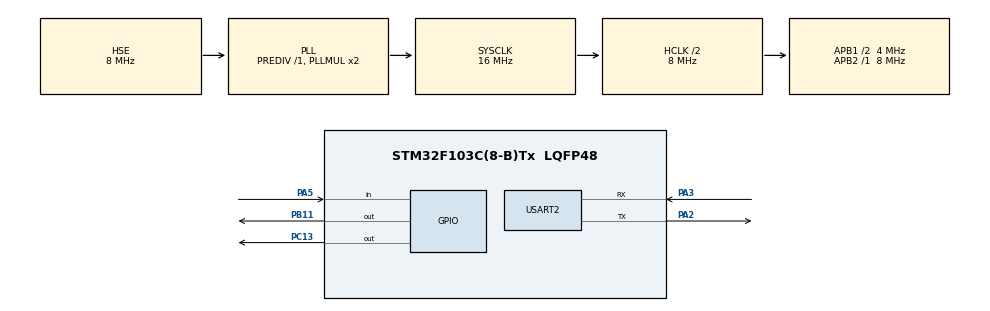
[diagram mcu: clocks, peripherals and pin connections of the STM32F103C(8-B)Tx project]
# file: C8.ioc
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Mcu.Family=STM32F1
RCC.PLLSourceVirtual=RCC_PLLSOURCE_HSE
PC15-OSC32_OUT.Mode=LSE-External-Oscillator
PD1-OSC_OUT.Mode=HSE-External-Oscillator
PC13-TAMPER-RTC.Signal=GPIO_Output
PD0-OSC_IN.Signal=RCC_OSC_IN
RCC.APB1CLKDivider=RCC_HCLK_DIV2
PC14-OSC32_IN.Signal=RCC_OSC32_IN
PB11.Signal=GPIO_Output
RCC.SYSCLKSource=RCC_SYSCLKSOURCE_PLLCLK
ProjectManager.StackSize=0x400
PD1-OSC_OUT.Signal=RCC_OSC_OUT
PA13.Signal=SYS_JTMS-SWDIO
PA3.Mode=Asynchronous
ProjectManager.TargetToolchain=STM32CubeIDE
RCC.HCLKFreq_Value=8000000
RCC.APB2TimFreq_Value=8000000
RCC.USBFreq_Value=16000000
PC15-OSC32_OUT.Signal=RCC_OSC32_OUT
RCC.AHBFreq_Value=8000000
PD0-OSC_IN.Mode=HSE-External-Oscillator
PA5.Signal=GPIO_Input
board=custom
RCC.APB2Freq_Value=8000000
PC14-OSC32_IN.Mode=LSE-External-Oscillator
PA14.Mode=Serial_Wire
RCC.AHBCLKDivider=RCC_SYSCLK_DIV2
PA13.Mode=Serial_Wire
Mcu.Name=STM32F103C(8-B)Tx
PA2.Signal=USART2_TX
RCC.SYSCLKFreq_VALUE=16000000
Mcu.Package=LQFP48
USART2.VirtualMode=VM_ASYNC
PA14.Signal=SYS_JTCK-SWCLK
ProjectManager.HeapSize=0x200
NVIC.PriorityGroup=NVIC_PRIORITYGROUP_4
RCC.APB1TimFreq_Value=8000000
PA2.Mode=Asynchronous
RCC.APB1Freq_Value=4000000
PA3.Signal=USART2_RX

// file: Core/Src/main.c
/* USER CODE BEGIN Header */
/**
  ******************************************************************************
  * @file           : main.c
  * @brief          : Main program body
  ******************************************************************************
  * @attention
  *
  * <h2><center>&copy; Copyright (c) 2025 STMicroelectronics.
  * All rights reserved.</center></h2>
  *
  * This software component is licensed by ST under BSD 3-Clause license,
  * the "License"; You may not use this file except in compliance with the
  * License. You may obtain a copy of the License at:
  *                        opensource.org/licenses/BSD-3-Clause
  *
  ******************************************************************************
  */
/* USER CODE END Header */
#include "main.h"

UART_HandleTypeDef huart2;

void SystemClock_Config(void);
static void MX_GPIO_Init(void);
static void MX_USART2_UART_Init(void);

int main(void)
{

  /* MCU Configuration--------------------------------------------------------*/

  /* Reset of all peripherals, Initializes the Flash interface and the Systick. */
  HAL_Init();

  /* Configure the system clock */
  SystemClock_Config();

  /* Initialize all configured peripherals */
  MX_GPIO_Init();
  MX_USART2_UART_Init();

  /* Infinite loop */
  /* USER CODE BEGIN WHILE */
  char buf[100];
  while (1)
  {
    /* USER CODE END WHILE */

    /* USER CODE BEGIN 3 */
	  strcpy(buf, "Hello K66 UET");
	  HAL_UART_Transmit(&huart2,(uint8_t*)buf, strlen(buf), HAL_MAX_DELAY);
	  HAL_GPIO_TogglePin(GPIOB, GPIO_PIN_11);
	  GPIO_PinState pin_state =  HAL_GPIO_ReadPin(GPIOA, GPIO_PIN_5);
	  HAL_GPIO_WritePin(GPIOC, GPIO_PIN_13, pin_state);

	  HAL_Delay(200);
  }
  /* USER CODE END 3 */
}

void SystemClock_Config(void)
{
  RCC_OscInitTypeDef RCC_OscInitStruct = {0};
  RCC_ClkInitTypeDef RCC_ClkInitStruct = {0};

  /** Initializes the RCC Oscillators according to the specified parameters
  * in the RCC_OscInitTypeDef structure.
  */
  RCC_OscInitStruct.OscillatorType = RCC_OSCILLATORTYPE_HSE;
  RCC_OscInitStruct.HSEState = RCC_HSE_ON;
  RCC_OscInitStruct.HSEPredivValue = RCC_HSE_PREDIV_DIV1;
  RCC_OscInitStruct.HSIState = RCC_HSI_ON;
  RCC_OscInitStruct.PLL.PLLState = RCC_PLL_ON;
  RCC_OscInitStruct.PLL.PLLSource = RCC_PLLSOURCE_HSE;
  RCC_OscInitStruct.PLL.PLLMUL = RCC_PLL_MUL2;
  if (HAL_RCC_OscConfig(&RCC_OscInitStruct) != HAL_OK)
  {
    Error_Handler();
  }
  /** Initializes the CPU, AHB and APB buses clocks
  */
  RCC_ClkInitStruct.ClockType = RCC_CLOCKTYPE_HCLK|RCC_CLOCKTYPE_SYSCLK
                              |RCC_CLOCKTYPE_PCLK1|RCC_CLOCKTYPE_PCLK2;
  RCC_ClkInitStruct.SYSCLKSource = RCC_SYSCLKSOURCE_PLLCLK;
  RCC_ClkInitStruct.AHBCLKDivider = RCC_SYSCLK_DIV2;
  RCC_ClkInitStruct.APB1CLKDivider = RCC_HCLK_DIV2;
  RCC_ClkInitStruct.APB2CLKDivider = RCC_HCLK_DIV1;

  if (HAL_RCC_ClockConfig(&RCC_ClkInitStruct, FLASH_LATENCY_0) != HAL_OK)
  {
    Error_Handler();
  }
}

static void MX_USART2_UART_Init(void)
{

  huart2.Instance = USART2;
  huart2.Init.BaudRate = 115200;
  huart2.Init.WordLength = UART_WORDLENGTH_8B;
  huart2.Init.StopBits = UART_STOPBITS_1;
  huart2.Init.Parity = UART_PARITY_NONE;
  huart2.Init.Mode = UART_MODE_TX_RX;
  huart2.Init.HwFlowCtl = UART_HWCONTROL_NONE;
  huart2.Init.OverSampling = UART_OVERSAMPLING_16;
  if (HAL_UART_Init(&huart2) != HAL_OK)
  {
    Error_Handler();
  }

}

static void MX_GPIO_Init(void)
{
  GPIO_InitTypeDef GPIO_InitStruct = {0};

  /* GPIO Ports Clock Enable */
  __HAL_RCC_GPIOC_CLK_ENABLE();
  __HAL_RCC_GPIOD_CLK_ENABLE();
  __HAL_RCC_GPIOA_CLK_ENABLE();
  __HAL_RCC_GPIOB_CLK_ENABLE();

  /*Configure GPIO pin Output Level */
  HAL_GPIO_WritePin(GPIOC, GPIO_PIN_13, GPIO_PIN_RESET);

  /*Configure GPIO pin Output Level */
  HAL_GPIO_WritePin(GPIOB, GPIO_PIN_11, GPIO_PIN_RESET);

  /*Configure GPIO pin : PC13 */
  GPIO_InitStruct.Pin = GPIO_PIN_13;
  GPIO_InitStruct.Mode = GPIO_MODE_OUTPUT_PP;
  GPIO_InitStruct.Pull = GPIO_NOPULL;
  GPIO_InitStruct.Speed = GPIO_SPEED_FREQ_LOW;
  HAL_GPIO_Init(GPIOC, &GPIO_InitStruct);

  /*Configure GPIO pin : PA5 */
  GPIO_InitStruct.Pin = GPIO_PIN_5;
  GPIO_InitStruct.Mode = GPIO_MODE_INPUT;
  GPIO_InitStruct.Pull = GPIO_NOPULL;
  HAL_GPIO_Init(GPIOA, &GPIO_InitStruct);

  /*Configure GPIO pin : PB11 */
  GPIO_InitStruct.Pin = GPIO_PIN_11;
  GPIO_InitStruct.Mode = GPIO_MODE_OUTPUT_PP;
  GPIO_InitStruct.Pull = GPIO_NOPULL;
  GPIO_InitStruct.Speed = GPIO_SPEED_FREQ_LOW;
  HAL_GPIO_Init(GPIOB, &GPIO_InitStruct);

}

void Error_Handler(void)
{
  __disable_irq();
  while (1)
  {
  }
}

/************************ (C) COPYRIGHT STMicroelectronics *****END OF FILE****/
